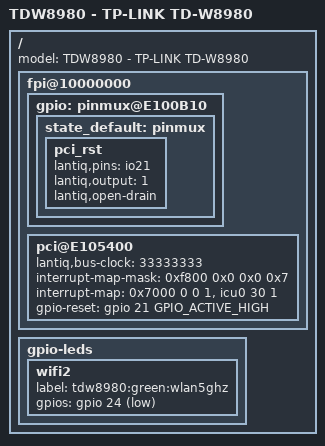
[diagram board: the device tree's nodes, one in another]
/dts-v1/;

#include "TDW89X0.dtsi"

/ {
	model = "TDW8980 - TP-LINK TD-W8980";

	fpi@10000000 {
		gpio: pinmux@E100B10 {
			state_default: pinmux {
				pci_rst {
					lantiq,pins = "io21";
					lantiq,output = <1>;
					lantiq,open-drain;
				};
			};
		};

		pci@E105400 {
			status = "okay";
			lantiq,bus-clock = <33333333>;
			interrupt-map-mask = <0xf800 0x0 0x0 0x7>;
			interrupt-map = <0x7000 0 0 1 &icu0 30 1>;
			gpio-reset = <&gpio 21 GPIO_ACTIVE_HIGH>;
		};
	};

	gpio-leds {
		wifi2 {
			label = "tdw8980:green:wlan5ghz";
			gpios = <&gpio 24 GPIO_ACTIVE_LOW>;
		};
	};
};
